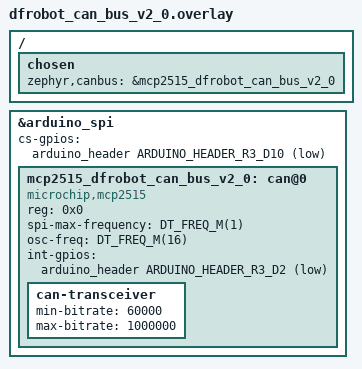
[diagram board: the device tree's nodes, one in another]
/*
 * Copyright (c) 2019 Karsten Koenig
 *
 * SPDX-License-Identifier: Apache-2.0
 */

#include <zephyr/dt-bindings/gpio/arduino-header-r3.h>
#include <zephyr/dt-bindings/gpio/gpio.h>
#include <freq.h>

/ {
	chosen {
		zephyr,canbus = &mcp2515_dfrobot_can_bus_v2_0;
	};
};

&arduino_spi {
	status = "okay";
	cs-gpios = <&arduino_header ARDUINO_HEADER_R3_D10 GPIO_ACTIVE_LOW>;

	mcp2515_dfrobot_can_bus_v2_0: can@0 {
		compatible = "microchip,mcp2515";
		reg = <0x0>;
		spi-max-frequency = <DT_FREQ_M(1)>;
		osc-freq = <DT_FREQ_M(16)>;
		int-gpios = <&arduino_header ARDUINO_HEADER_R3_D2 GPIO_ACTIVE_LOW>;
		status = "okay";

		can-transceiver {
			min-bitrate = <60000>;
			max-bitrate = <1000000>;
		};
	};
};
